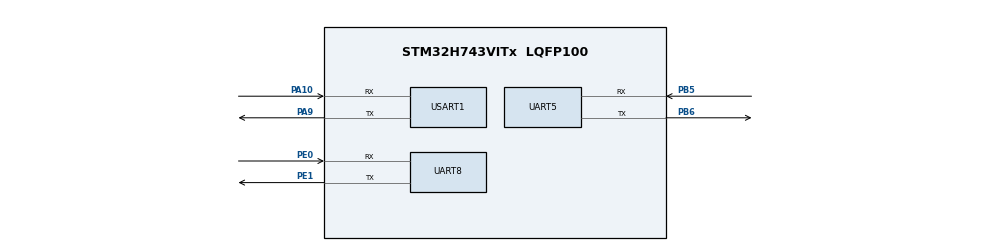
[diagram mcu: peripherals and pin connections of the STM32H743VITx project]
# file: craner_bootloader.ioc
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Dma.Request0=USART1_RX
Dma.Request1=USART1_TX
Dma.Request2=UART8_RX
Dma.Request3=UART8_TX
Dma.Request4=UART5_RX
Dma.Request5=UART5_TX
Dma.UART5_RX.4.Direction=DMA_PERIPH_TO_MEMORY
Dma.UART5_RX.4.EventEnable=DISABLE
Dma.UART5_RX.4.FIFOMode=DMA_FIFOMODE_DISABLE
Dma.UART5_RX.4.Instance=DMA1_Stream4
Dma.UART5_RX.4.MemDataAlignment=DMA_MDATAALIGN_BYTE
Dma.UART5_RX.4.MemInc=DMA_MINC_ENABLE
Dma.UART5_RX.4.Mode=DMA_NORMAL
Dma.UART5_RX.4.PeriphDataAlignment=DMA_PDATAALIGN_BYTE
Dma.UART5_RX.4.PeriphInc=DMA_PINC_DISABLE
Dma.UART5_RX.4.Polarity=HAL_DMAMUX_REQ_GEN_RISING
Dma.UART5_RX.4.Priority=DMA_PRIORITY_LOW
Dma.UART5_RX.4.RequestNumber=1
Dma.UART5_RX.4.SignalID=NONE
Dma.UART5_RX.4.SyncEnable=DISABLE
Dma.UART5_RX.4.SyncPolarity=HAL_DMAMUX_SYNC_NO_EVENT
Dma.UART5_RX.4.SyncRequestNumber=1
Dma.UART5_RX.4.SyncSignalID=NONE
Dma.UART5_TX.5.Direction=DMA_MEMORY_TO_PERIPH
Dma.UART5_TX.5.EventEnable=DISABLE
Dma.UART5_TX.5.FIFOMode=DMA_FIFOMODE_DISABLE
Dma.UART5_TX.5.Instance=DMA1_Stream5
Dma.UART5_TX.5.MemDataAlignment=DMA_MDATAALIGN_BYTE
Dma.UART5_TX.5.MemInc=DMA_MINC_ENABLE
Dma.UART5_TX.5.Mode=DMA_NORMAL
Dma.UART5_TX.5.PeriphDataAlignment=DMA_PDATAALIGN_BYTE
Dma.UART5_TX.5.PeriphInc=DMA_PINC_DISABLE
Dma.UART5_TX.5.Polarity=HAL_DMAMUX_REQ_GEN_RISING
Dma.UART5_TX.5.Priority=DMA_PRIORITY_LOW
Dma.UART5_TX.5.RequestNumber=1
Dma.UART5_TX.5.SignalID=NONE
Dma.UART5_TX.5.SyncEnable=DISABLE
Dma.UART5_TX.5.SyncPolarity=HAL_DMAMUX_SYNC_NO_EVENT
Dma.UART5_TX.5.SyncRequestNumber=1
Dma.UART5_TX.5.SyncSignalID=NONE
Dma.UART8_RX.2.Direction=DMA_PERIPH_TO_MEMORY
Dma.UART8_RX.2.EventEnable=DISABLE
Dma.UART8_RX.2.FIFOMode=DMA_FIFOMODE_DISABLE
Dma.UART8_RX.2.Instance=DMA1_Stream2
Dma.UART8_RX.2.MemDataAlignment=DMA_MDATAALIGN_BYTE
Dma.UART8_RX.2.MemInc=DMA_MINC_ENABLE
Dma.UART8_RX.2.Mode=DMA_NORMAL
Dma.UART8_RX.2.PeriphDataAlignment=DMA_PDATAALIGN_BYTE
Dma.UART8_RX.2.PeriphInc=DMA_PINC_DISABLE
Dma.UART8_RX.2.Polarity=HAL_DMAMUX_REQ_GEN_RISING
Dma.UART8_RX.2.Priority=DMA_PRIORITY_VERY_HIGH
Dma.UART8_RX.2.RequestNumber=1
Dma.UART8_RX.2.SignalID=NONE
Dma.UART8_RX.2.SyncEnable=DISABLE
Dma.UART8_RX.2.SyncPolarity=HAL_DMAMUX_SYNC_NO_EVENT
Dma.UART8_RX.2.SyncRequestNumber=1
Dma.UART8_RX.2.SyncSignalID=NONE
Dma.UART8_TX.3.Direction=DMA_MEMORY_TO_PERIPH
Dma.UART8_TX.3.EventEnable=DISABLE
Dma.UART8_TX.3.FIFOMode=DMA_FIFOMODE_DISABLE
Dma.UART8_TX.3.Instance=DMA1_Stream3
Dma.UART8_TX.3.MemDataAlignment=DMA_MDATAALIGN_BYTE
Dma.UART8_TX.3.MemInc=DMA_MINC_ENABLE
Dma.UART8_TX.3.Mode=DMA_NORMAL
Dma.UART8_TX.3.PeriphDataAlignment=DMA_PDATAALIGN_BYTE
Dma.UART8_TX.3.PeriphInc=DMA_PINC_DISABLE
Dma.UART8_TX.3.Polarity=HAL_DMAMUX_REQ_GEN_RISING
Dma.UART8_TX.3.Priority=DMA_PRIORITY_VERY_HIGH
Dma.UART8_TX.3.RequestNumber=1
Dma.UART8_TX.3.SignalID=NONE
Dma.UART8_TX.3.SyncEnable=DISABLE
Dma.UART8_TX.3.SyncPolarity=HAL_DMAMUX_SYNC_NO_EVENT
Dma.UART8_TX.3.SyncRequestNumber=1
Dma.UART8_TX.3.SyncSignalID=NONE
Dma.USART1_RX.0.Direction=DMA_PERIPH_TO_MEMORY
Dma.USART1_RX.0.EventEnable=DISABLE
Dma.USART1_RX.0.FIFOMode=DMA_FIFOMODE_DISABLE
Dma.USART1_RX.0.Instance=DMA1_Stream0
Dma.USART1_RX.0.MemDataAlignment=DMA_MDATAALIGN_BYTE
Dma.USART1_RX.0.MemInc=DMA_MINC_ENABLE
Dma.USART1_RX.0.Mode=DMA_NORMAL
Dma.USART1_RX.0.PeriphDataAlignment=DMA_PDATAALIGN_BYTE
Dma.USART1_RX.0.PeriphInc=DMA_PINC_DISABLE
Dma.USART1_RX.0.Polarity=HAL_DMAMUX_REQ_GEN_RISING
Dma.USART1_RX.0.Priority=DMA_PRIORITY_LOW
Dma.USART1_RX.0.RequestNumber=1
Dma.USART1_RX.0.SignalID=NONE
Dma.USART1_RX.0.SyncEnable=DISABLE
Dma.USART1_RX.0.SyncPolarity=HAL_DMAMUX_SYNC_NO_EVENT
Dma.USART1_RX.0.SyncRequestNumber=1
Dma.USART1_RX.0.SyncSignalID=NONE
Dma.USART1_TX.1.Direction=DMA_MEMORY_TO_PERIPH
Dma.USART1_TX.1.EventEnable=DISABLE
Dma.USART1_TX.1.FIFOMode=DMA_FIFOMODE_DISABLE
Dma.USART1_TX.1.Instance=DMA1_Stream1
Dma.USART1_TX.1.MemDataAlignment=DMA_MDATAALIGN_BYTE
Dma.USART1_TX.1.MemInc=DMA_MINC_ENABLE
Dma.USART1_TX.1.Mode=DMA_NORMAL
Dma.USART1_TX.1.PeriphDataAlignment=DMA_PDATAALIGN_BYTE
Dma.USART1_TX.1.PeriphInc=DMA_PINC_DISABLE
Dma.USART1_TX.1.Polarity=HAL_DMAMUX_REQ_GEN_RISING
Dma.USART1_TX.1.Priority=DMA_PRIORITY_LOW
Dma.USART1_TX.1.RequestNumber=1
Dma.USART1_TX.1.SignalID=NONE
Dma.USART1_TX.1.SyncEnable=DISABLE
Dma.USART1_TX.1.SyncPolarity=HAL_DMAMUX_SYNC_NO_EVENT
Dma.USART1_TX.1.SyncRequestNumber=1
Dma.USART1_TX.1.SyncSignalID=NONE
Mcu.Family=STM32H7
Mcu.Name=STM32H743VITx
Mcu.Package=LQFP100
NVIC.DMA1_Stream0_IRQn=true\:0\:0\:false\:false\:true\:false\:true\:true
NVIC.DMA1_Stream1_IRQn=true\:0\:0\:false\:false\:true\:false\:true\:true
NVIC.DMA1_Stream2_IRQn=true\:0\:0\:false\:false\:true\:false\:true\:true
NVIC.DMA1_Stream3_IRQn=true\:0\:0\:false\:false\:true\:false\:true\:true
NVIC.DMA1_Stream4_IRQn=true\:0\:0\:false\:false\:true\:false\:true\:true
NVIC.DMA1_Stream5_IRQn=true\:0\:0\:false\:false\:true\:false\:true\:true
NVIC.PriorityGroup=NVIC_PRIORITYGROUP_4
NVIC.UART5_IRQn=true\:0\:0\:false\:false\:true\:true\:true\:true
NVIC.UART8_IRQn=true\:0\:0\:false\:false\:true\:true\:true\:true
NVIC.USART1_IRQn=true\:0\:0\:false\:false\:true\:true\:true\:true
PA10.Mode=Asynchronous
PA10.Signal=USART1_RX
PA9.Mode=Asynchronous
PA9.Signal=USART1_TX
PB5.Mode=Asynchronous
PB5.Signal=UART5_RX
PB6.Mode=Asynchronous
PB6.Signal=UART5_TX
PE0.Mode=Asynchronous
PE0.Signal=UART8_RX
PE1.Mode=Asynchronous
PE1.Signal=UART8_TX
ProjectManager.HeapSize=0x200
ProjectManager.StackSize=0x400
ProjectManager.TargetToolchain=STM32CubeIDE
RCC.ADCFreq_Value=129000000
RCC.APB1Freq_Value=32000000
RCC.APB2Freq_Value=32000000
RCC.APB3Freq_Value=64000000
RCC.APB4Freq_Value=64000000
RCC.CortexFreq_Value=64000000
RCC.D2PPRE1=RCC_APB1_DIV2
RCC.D2PPRE2=RCC_APB2_DIV2
RCC.HCLKFreq_Value=64000000
RCC.SYSCLKFreq_VALUE=64000000
RCC.USBFreq_Value=129000000
USART1.VirtualMode-Asynchronous=VM_ASYNC
VP_MEMORYMAP_VS_MEMORYMAP.Mode=CurAppReg
board=custom

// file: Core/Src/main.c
/* USER CODE BEGIN Header */
/**
  ******************************************************************************
  * @file           : main.c
  * @brief          : Main program body
  ******************************************************************************
  * @attention
  *
  * Copyright (c) 2026 STMicroelectronics.
  * All rights reserved.
  *
  * This software is licensed under terms that can be found in the LICENSE file
  * in the root directory of this software component.
  * If no LICENSE file comes with this software, it is provided AS-IS.
  *
  ******************************************************************************
  */
/* USER CODE END Header */
#include <uart_manage_port.h>
#include "main.h"

/* USER CODE BEGIN Includes */
#include "ota_manage_service.h"
/* USER CODE END Includes */

UART_HandleTypeDef huart5;
UART_HandleTypeDef huart8;
UART_HandleTypeDef huart1;
DMA_HandleTypeDef hdma_uart5_rx;
DMA_HandleTypeDef hdma_uart5_tx;
DMA_HandleTypeDef hdma_uart8_rx;
DMA_HandleTypeDef hdma_uart8_tx;
DMA_HandleTypeDef hdma_usart1_rx;
DMA_HandleTypeDef hdma_usart1_tx;

void SystemClock_Config(void);
static void MX_GPIO_Init(void);
static void MX_DMA_Init(void);
static void MX_USART1_UART_Init(void);
static void MX_UART8_Init(void);
static void MX_UART5_Init(void);

int main(void)
{

  /* MCU Configuration--------------------------------------------------------*/

  /* Reset of all peripherals, Initializes the Flash interface and the Systick. */
  HAL_Init();

  /* Configure the system clock */
  SystemClock_Config();

  /* Initialize all configured peripherals */
  MX_GPIO_Init();
  MX_DMA_Init();
  MX_USART1_UART_Init();
  MX_UART8_Init();
  MX_UART5_Init();
  /* USER CODE BEGIN 2 */
  (void)uart_service_init_port();
  (void)shell_interface_printf("\r\n[I][BOOT] craner bootloader start\r\n");
  (void)shell_interface_printf("[I][BOOT] uart shell=UART5 mqtt=USART1\r\n");
  (void)ota_manage_service_init();
  (void)ota_manage_service_start();

  /* USER CODE END 2 */

  /* Infinite loop */
  while (1)
  {

    /* USER CODE BEGIN 3 */
    ota_manage_service_process(HAL_GetTick());
    HAL_Delay(1U);
  }
  /* USER CODE END 3 */
}

void SystemClock_Config(void)
{
  RCC_OscInitTypeDef RCC_OscInitStruct = {0};
  RCC_ClkInitTypeDef RCC_ClkInitStruct = {0};

  /** Supply configuration update enable
  */
  HAL_PWREx_ConfigSupply(PWR_LDO_SUPPLY);

  /** Configure the main internal regulator output voltage
  */
  __HAL_PWR_VOLTAGESCALING_CONFIG(PWR_REGULATOR_VOLTAGE_SCALE3);

  while(!__HAL_PWR_GET_FLAG(PWR_FLAG_VOSRDY)) {}

  /** Initializes the RCC Oscillators according to the specified parameters
  * in the RCC_OscInitTypeDef structure.
  */
  RCC_OscInitStruct.OscillatorType = RCC_OSCILLATORTYPE_HSI;
  RCC_OscInitStruct.HSIState = RCC_HSI_DIV1;
  RCC_OscInitStruct.HSICalibrationValue = RCC_HSICALIBRATION_DEFAULT;
  RCC_OscInitStruct.PLL.PLLState = RCC_PLL_NONE;
  if (HAL_RCC_OscConfig(&RCC_OscInitStruct) != HAL_OK)
  {
    Error_Handler();
  }

  /** Initializes the CPU, AHB and APB buses clocks
  */
  RCC_ClkInitStruct.ClockType = RCC_CLOCKTYPE_HCLK|RCC_CLOCKTYPE_SYSCLK
                              |RCC_CLOCKTYPE_PCLK1|RCC_CLOCKTYPE_PCLK2
                              |RCC_CLOCKTYPE_D3PCLK1|RCC_CLOCKTYPE_D1PCLK1;
  RCC_ClkInitStruct.SYSCLKSource = RCC_SYSCLKSOURCE_HSI;
  RCC_ClkInitStruct.SYSCLKDivider = RCC_SYSCLK_DIV1;
  RCC_ClkInitStruct.AHBCLKDivider = RCC_HCLK_DIV1;
  RCC_ClkInitStruct.APB3CLKDivider = RCC_APB3_DIV1;
  RCC_ClkInitStruct.APB1CLKDivider = RCC_APB1_DIV2;
  RCC_ClkInitStruct.APB2CLKDivider = RCC_APB2_DIV2;
  RCC_ClkInitStruct.APB4CLKDivider = RCC_APB4_DIV1;

  if (HAL_RCC_ClockConfig(&RCC_ClkInitStruct, FLASH_LATENCY_1) != HAL_OK)
  {
    Error_Handler();
  }
}

static void MX_UART5_Init(void)
{

  huart5.Instance = UART5;
  huart5.Init.BaudRate = 115200;
  huart5.Init.WordLength = UART_WORDLENGTH_8B;
  huart5.Init.StopBits = UART_STOPBITS_1;
  huart5.Init.Parity = UART_PARITY_NONE;
  huart5.Init.Mode = UART_MODE_TX_RX;
  huart5.Init.HwFlowCtl = UART_HWCONTROL_NONE;
  huart5.Init.OverSampling = UART_OVERSAMPLING_16;
  huart5.Init.OneBitSampling = UART_ONE_BIT_SAMPLE_DISABLE;
  huart5.Init.ClockPrescaler = UART_PRESCALER_DIV1;
  huart5.AdvancedInit.AdvFeatureInit = UART_ADVFEATURE_NO_INIT;
  if (HAL_UART_Init(&huart5) != HAL_OK)
  {
    Error_Handler();
  }
  if (HAL_UARTEx_SetTxFifoThreshold(&huart5, UART_TXFIFO_THRESHOLD_1_8) != HAL_OK)
  {
    Error_Handler();
  }
  if (HAL_UARTEx_SetRxFifoThreshold(&huart5, UART_RXFIFO_THRESHOLD_1_8) != HAL_OK)
  {
    Error_Handler();
  }
  if (HAL_UARTEx_DisableFifoMode(&huart5) != HAL_OK)
  {
    Error_Handler();
  }

}

static void MX_UART8_Init(void)
{

  huart8.Instance = UART8;
  huart8.Init.BaudRate = 115200;
  huart8.Init.WordLength = UART_WORDLENGTH_8B;
  huart8.Init.StopBits = UART_STOPBITS_1;
  huart8.Init.Parity = UART_PARITY_NONE;
  huart8.Init.Mode = UART_MODE_TX_RX;
  huart8.Init.HwFlowCtl = UART_HWCONTROL_NONE;
  huart8.Init.OverSampling = UART_OVERSAMPLING_16;
  huart8.Init.OneBitSampling = UART_ONE_BIT_SAMPLE_DISABLE;
  huart8.Init.ClockPrescaler = UART_PRESCALER_DIV1;
  huart8.AdvancedInit.AdvFeatureInit = UART_ADVFEATURE_NO_INIT;
  if (HAL_UART_Init(&huart8) != HAL_OK)
  {
    Error_Handler();
  }
  if (HAL_UARTEx_SetTxFifoThreshold(&huart8, UART_TXFIFO_THRESHOLD_1_8) != HAL_OK)
  {
    Error_Handler();
  }
  if (HAL_UARTEx_SetRxFifoThreshold(&huart8, UART_RXFIFO_THRESHOLD_1_8) != HAL_OK)
  {
    Error_Handler();
  }
  if (HAL_UARTEx_DisableFifoMode(&huart8) != HAL_OK)
  {
    Error_Handler();
  }

}

static void MX_USART1_UART_Init(void)
{

  huart1.Instance = USART1;
  huart1.Init.BaudRate = 115200;
  huart1.Init.WordLength = UART_WORDLENGTH_8B;
  huart1.Init.StopBits = UART_STOPBITS_1;
  huart1.Init.Parity = UART_PARITY_NONE;
  huart1.Init.Mode = UART_MODE_TX_RX;
  huart1.Init.HwFlowCtl = UART_HWCONTROL_NONE;
  huart1.Init.OverSampling = UART_OVERSAMPLING_16;
  huart1.Init.OneBitSampling = UART_ONE_BIT_SAMPLE_DISABLE;
  huart1.Init.ClockPrescaler = UART_PRESCALER_DIV1;
  huart1.AdvancedInit.AdvFeatureInit = UART_ADVFEATURE_NO_INIT;
  if (HAL_UART_Init(&huart1) != HAL_OK)
  {
    Error_Handler();
  }
  if (HAL_UARTEx_SetTxFifoThreshold(&huart1, UART_TXFIFO_THRESHOLD_1_8) != HAL_OK)
  {
    Error_Handler();
  }
  if (HAL_UARTEx_SetRxFifoThreshold(&huart1, UART_RXFIFO_THRESHOLD_1_8) != HAL_OK)
  {
    Error_Handler();
  }
  if (HAL_UARTEx_DisableFifoMode(&huart1) != HAL_OK)
  {
    Error_Handler();
  }

}

static void MX_DMA_Init(void)
{

  /* DMA controller clock enable */
  __HAL_RCC_DMA1_CLK_ENABLE();

  /* DMA interrupt init */
  /* DMA1_Stream0_IRQn interrupt configuration */
  HAL_NVIC_SetPriority(DMA1_Stream0_IRQn, 0, 0);
  HAL_NVIC_EnableIRQ(DMA1_Stream0_IRQn);
  /* DMA1_Stream1_IRQn interrupt configuration */
  HAL_NVIC_SetPriority(DMA1_Stream1_IRQn, 0, 0);
  HAL_NVIC_EnableIRQ(DMA1_Stream1_IRQn);
  /* DMA1_Stream2_IRQn interrupt configuration */
  HAL_NVIC_SetPriority(DMA1_Stream2_IRQn, 0, 0);
  HAL_NVIC_EnableIRQ(DMA1_Stream2_IRQn);
  /* DMA1_Stream3_IRQn interrupt configuration */
  HAL_NVIC_SetPriority(DMA1_Stream3_IRQn, 0, 0);
  HAL_NVIC_EnableIRQ(DMA1_Stream3_IRQn);
  /* DMA1_Stream4_IRQn interrupt configuration */
  HAL_NVIC_SetPriority(DMA1_Stream4_IRQn, 0, 0);
  HAL_NVIC_EnableIRQ(DMA1_Stream4_IRQn);
  /* DMA1_Stream5_IRQn interrupt configuration */
  HAL_NVIC_SetPriority(DMA1_Stream5_IRQn, 0, 0);
  HAL_NVIC_EnableIRQ(DMA1_Stream5_IRQn);

}

static void MX_GPIO_Init(void)
{

  /* GPIO Ports Clock Enable */
  __HAL_RCC_GPIOA_CLK_ENABLE();
  __HAL_RCC_GPIOB_CLK_ENABLE();
  __HAL_RCC_GPIOE_CLK_ENABLE();

}

void Error_Handler(void)
{
  __disable_irq();
  while (1)
  {
  }
}
